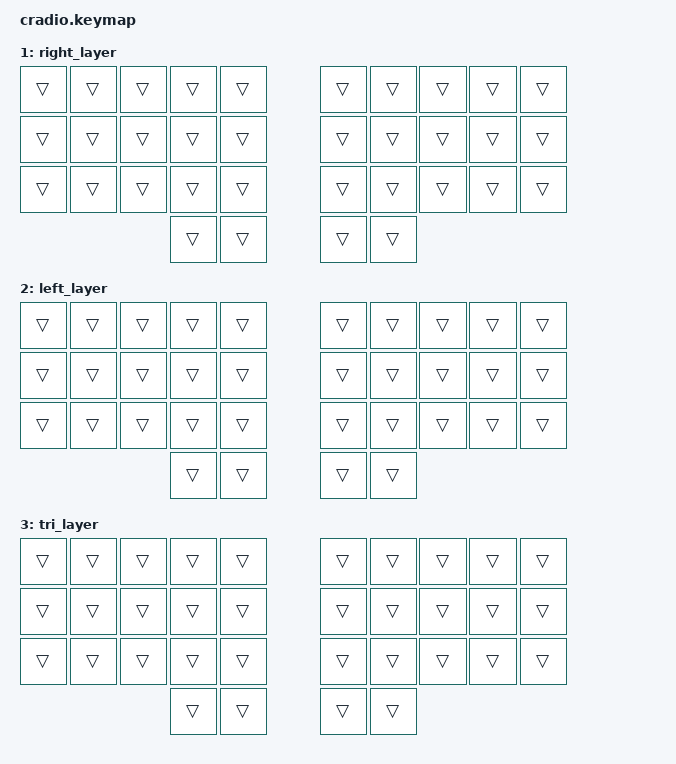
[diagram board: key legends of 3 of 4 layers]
// Copyright (c) 2022 The ZMK Contributors
// SPDX-License-Identifier: MIT

#include <behaviors.dtsi>
#include <dt-bindings/zmk/keys.h>
#include <dt-bindings/zmk/bt.h>

// Home row mods macro
#define HRML(k1,k2,k3,k4) &ht LSHFT k1  &ht LALT k2  &ht LCTRL k3  &ht LGUI k4
#define HRMR(k1,k2,k3,k4) &ht RGUI k1  &ht RCTRL k2  &ht RALT k3  &ht RSHFT k4

/ {
    behaviors {
        ht: hold_tap {
            compatible = "zmk,behavior-hold-tap";
            #binding-cells = <2>;
            flavor = "tap-preferred";
            tapping-term-ms = <220>;
            quick-tap-ms = <150>;
            require-prior-idle-ms = <100>;
            bindings = <&kp>, <&kp>;
        };
    };

    conditional_layers {
        compatible = "zmk,conditional-layers";
        tri_layer {
            if-layers = <1 2>;
            then-layer = <3>;
        };
    };

    keymap {
        compatible = "zmk,keymap";
        default_layer {
            bindings = <
        //╭──────────┬──────────┬──────────┬──────────┬──────────╮   ╭──────────┬──────────┬──────────┬──────────┬──────────╮
        //│  Q       │  W       │  E       │  R       │  T       │   │  Y       │  U       │  I       │  O       │  P       │
            &kp Q      &kp W      &kp E      &kp R      &kp T          &kp Y      &kp U      &kp I      &kp O      &kp P
        //├──────────┼──────────┼──────────┼──────────┼──────────┤   ├──────────┼──────────┼──────────┼──────────┼──────────┤
        //│  A       │  S       │  D       │  F       │  G       │   │  H       │  J       │  K       │  L       │ ' "      │
            HRML(A,        S,         D,         F)     &kp G          &kp H      HRMR(J,        K,         L,        SQT)
        //├──────────┼──────────┼──────────┼──────────┼──────────┤   ├──────────┼──────────┼──────────┼──────────┼──────────┤
        //│  Z       │  X       │  C       │  V       │  B       │   │  N       │  M       │ , <      │ . >      │ / ?      │
            &kp Z      &kp X      &kp C      &kp V      &kp B          &kp N      &kp M      &kp COMMA  &kp DOT    &kp FSLH
        //╰──────────┴──────────┴──────────┼──────────┼──────────┤   ├──────────┼──────────┼──────────┴──────────┴──────────╯
                                            &lt 2 ENTER &kp SPACE      &kp BSPC   &lt 1 ESC 
        //                                 ╰──────────┴──────────╯   ╰──────────┴──────────╯
            >;
        };

        right_layer {
            bindings = <
        //╭──────────┬──────────┬──────────┬──────────┬──────────╮   ╭──────────┬──────────┬──────────┬──────────┬──────────╮
        //│          │          │          │          │          │   │          │          │          │          │          │
            &trans     &trans     &trans     &trans     &trans          &trans     &trans     &trans     &trans     &trans
        //├──────────┼──────────┼──────────┼──────────┼──────────┤   ├──────────┼──────────┼──────────┼──────────┼──────────┤
        //│          │          │          │          │          │   │          │          │          │          │          │
            &trans     &trans     &trans     &trans     &trans          &trans     &trans     &trans     &trans     &trans
        //├──────────┼──────────┼──────────┼──────────┼──────────┤   ├──────────┼──────────┼──────────┼──────────┼──────────┤
        //│          │          │          │          │          │   │          │          │          │          │          │
            &trans     &trans     &trans     &trans     &trans          &trans     &trans     &trans     &trans     &trans
        //╰──────────┴──────────┴──────────┼──────────┼──────────┤   ├──────────┼──────────┼──────────┴──────────┴──────────╯
                                              &trans     &trans         &trans     &trans
        //                                 ╰──────────┴──────────╯   ╰──────────┴──────────╯
            >;
        };

        left_layer {
            bindings = <
        //╭──────────┬──────────┬──────────┬──────────┬──────────╮   ╭──────────┬──────────┬──────────┬──────────┬──────────╮
        //│          │          │          │          │          │   │          │          │          │          │          │
            &trans     &trans     &trans     &trans     &trans          &trans     &trans     &trans     &trans     &trans
        //├──────────┼──────────┼──────────┼──────────┼──────────┤   ├──────────┼──────────┼──────────┼──────────┼──────────┤
        //│          │          │          │          │          │   │          │          │          │          │          │
            &trans     &trans     &trans     &trans     &trans          &trans     &trans     &trans     &trans     &trans
        //├──────────┼──────────┼──────────┼──────────┼──────────┤   ├──────────┼──────────┼──────────┼──────────┼──────────┤
        //│          │          │          │          │          │   │          │          │          │          │          │
            &trans     &trans     &trans     &trans     &trans          &trans     &trans     &trans     &trans     &trans
        //╰──────────┴──────────┴──────────┼──────────┼──────────┤   ├──────────┼──────────┼──────────┴──────────┴──────────╯
                                              &trans     &trans         &trans     &trans
        //                                 ╰──────────┴──────────╯   ╰──────────┴──────────╯
            >;
        };

        tri_layer {
            bindings = <
        //╭──────────┬──────────┬──────────┬──────────┬──────────╮   ╭──────────┬──────────┬──────────┬──────────┬──────────╮
        //│          │          │          │          │          │   │          │          │          │          │          │
            &trans     &trans     &trans     &trans     &trans          &trans     &trans     &trans     &trans     &trans
        //├──────────┼──────────┼──────────┼──────────┼──────────┤   ├──────────┼──────────┼──────────┼──────────┼──────────┤
        //│          │          │          │          │          │   │          │          │          │          │          │
            &trans     &trans     &trans     &trans     &trans          &trans     &trans     &trans     &trans     &trans
        //├──────────┼──────────┼──────────┼──────────┼──────────┤   ├──────────┼──────────┼──────────┼──────────┼──────────┤
        //│          │          │          │          │          │   │          │          │          │          │          │
            &trans     &trans     &trans     &trans     &trans          &trans     &trans     &trans     &trans     &trans
        //╰──────────┴──────────┴──────────┼──────────┼──────────┤   ├──────────┼──────────┼──────────┴──────────┴──────────╯
                                              &trans     &trans         &trans     &trans
        //                                 ╰──────────┴──────────╯   ╰──────────┴──────────╯
            >;
        };
    };
};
